# YC3122 register map
Series: ARMCM0; File version: 1.0
CPU: CM0 r1p0, little endian, no MPU, no FPU, 8 interrupt priority bits
Registers are 32-bit, read-write, reset 0x0 unless marked. A register's access mark holds for its fields unless they carry their own. Offsets are from the block's base; [hi:lo] are bit positions; <NAME> marks a mode.

## MSCI0
Base 0x000F0400
Same registers: MSCI1 0x000F0800
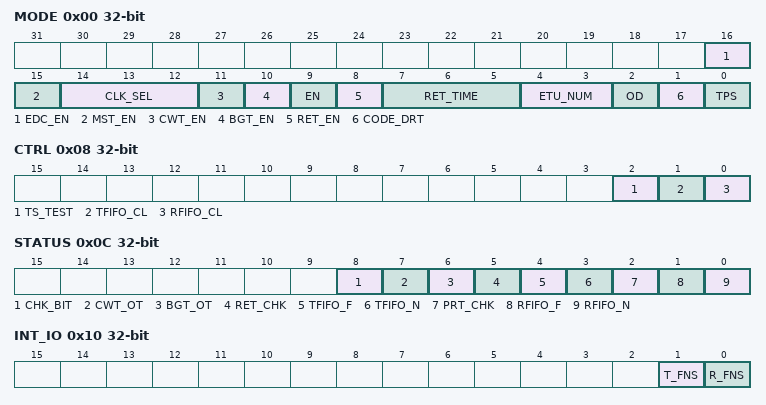
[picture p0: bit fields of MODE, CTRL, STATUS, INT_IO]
0x00 MODE
  [16] EDC_EN — EDC错误检测使能 0: 失能 1: 使能
  [15] MST_EN — 主机模式使能 0: 失能 1: 使能
  [14:12] CLK_SEL — CLK时钟源控制位(PWM0~PWM7)
  [11] CWT_EN — CWT计时器使能 0: 失能 1: 使能
  [10] BGT_EN — 块保护时间使能 0: 失能 1: 使能
  [9] EN — SCI7816使能 0: 失能 1: 使能
  [8] RET_EN — 重传使能位 0:失能 1:使能
  [7:5] RET_TIME — 重传次数
  [4:3] ETU_NUM — ETU个数控制位
  [2] OD — OD控制位 0: 开漏模式 1: 推挽模式(default)
  [1] CODE_DRT — 编码选择控制位 0:正向编码 1:反向编码
  [0] TPS — 模式控制位 0:T=0. 1:T=1
0x08 CTRL
  [2] TS_TEST — 检测TS字节 0:不起作用 1:接收到数据为03时校验位电平取反
  [1] TFIFO_CL — 发送FIFO内容清除控制位 0:不起作用 1:清除FIFO内数据
  [0] RFIFO_CL — 接收FIFO内容清除控制位 0:不起作用 1:清除FIFO内数据
0x0C STATUS
  [8] CHK_BIT — 检验位状态 0:检验位正确 1:检验位错误
  [7] CWT_OT — CWT超时状态位 0:没超时 1:超时 (参考:SCI7816_CWT寄存器说明）
  [6] BGT_OT — BGT超时状态位 0:没超时 1:超时 (参考:SCI7816_BGT寄存器说明）
  [5] RET_CHK — 重传奇偶校验检测状态位 0: 奇偶校验正确 1: 奇偶校验错误（在重传功能开启时,只有在发送达到重传 次数时仍有错误发生,此位才被置位）
  [4] TFIFO_F — 发送缓冲器满状态位 0: 发送缓冲器不满 1: 发送缓冲器满
  [3] TFIFO_N — 发送缓冲器空状态位 0: 发送缓冲器空 1: 发送缓冲器中不空
  [2] PRT_CHK — 奇偶校验状态位 0: 奇偶校验正确 1: 奇偶校验错误
  [1] RFIFO_F — 接收缓冲器满状态位 0:接收缓冲器不满 1:接收缓冲器满
  [0] RFIFO_N — 接收缓冲器空状态位 0:接收缓冲器空 1:接收缓冲器中不空
0x10 INT_IO
  [1] T_FNS — 发送完成标志位 0:没发送完成 1:已发送完成
  [0] R_FNS — 接收完成标志位 0:没接收完成 1:已接收完成
0x20 DATA
  [7:0] VAL — 在发送或接收模式下分别充当发送或接收buffer 角色
0x28 ETU
  [12:0] VAL — 配置SCI7816通讯速率
0x2C BGT
  [5:0] VAL — 配置SCI7816块反向发送时间间隔,max 6. 3
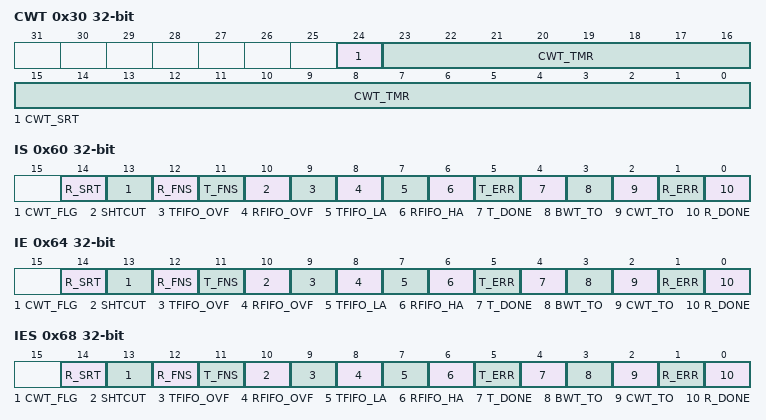
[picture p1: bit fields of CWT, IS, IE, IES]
0x30 CWT
  [24] CWT_SRT — CWT计时开始 0:CWT未开始计时 1:CWT计时立即生效
  [23:0] CWT_TMR — 配置SCI7816CWT定时值,发送字节完成,接 收起始时启动计时
0x34 EDC
  [7:0] VAL — 保存 LRC 计算结果
0x60 IS
  [14] R_SRT — 接收到毛刺信号,会触发此中断,仅rx_en使能时 会触发 bwt期间,bwt会自动恢复重启,可以触发超时 cwt期间,毛刺到来会重置cwt计数器,wt超时时间会变 长
  [13] CWT_FLG — cwt标志, 写 '1' 清除 IS 和 IES
  [12] R_FNS — 接收完成
  [11] T_FNS — 发送完成
  [10] SHTCUT
  [9] TFIFO_OVF — 主机写入 发送FIFO 时 发送FIFO 满,T. FIFO_OVF 溢出中断 接收时,主机读 FIFO 下溢可能会导致此中断断言
  [8] RFIFO_OVF — 设备接收字节时 接收FIFO 满,RFIFO_O. VF 溢出中断
  [7] TFIFO_LA — T_ITEMS <= TL_WTL 发生中断后,应首先填充T_ITEMS至水线以上,或改变水 线,才能清除中断 TL_WTL为0时,不触发此中断
  [6] RFIFO_HA — R_ITEMS <= RH_WTL 发生中断后,应首先读取rx_fifo至水线以下,或改变水 线,才能清除中断 RH_WTL为0时,不触发此中断
  [5] T_ERR — 发送错误,T0 重试次数超过配置,T1 从未触发 此错误
  [4] T_DONE — 成功传输 FIFO 中的最后一个字节
  [3] BWT_TO — 接收 BWT 定时器超时中断
  [2] CWT_TO — 接收 CWT 定时器超时中断
  [1] R_ERR — 接收错误中断,T0 重试次数超过配置,T1 奇偶 校验错误
  [0] R_DONE — 成功接收到1个字节
0x64 IE
  [14] R_SRT — 使能 R_SRT 中断控制位
  [13] CWT_FLG — 使能 CWT_FLG 中断控制位
  [12] R_FNS — 使能 R_FNS 中断控制位
  [11] T_FNS — 使能 T_FNS 中断控制位
  [10] SHTCUT — 使能 SHTCUT 中断控制位
  [9] TFIFO_OVF — 使能 TFIFO_OVF 中断控制位
  [8] RFIFO_OVF — 使能 RFIFO_OVF 中断控制位
  [7] TFIFO_LA — 使能 TFIFO_LA 中断控制位
  [6] RFIFO_HA — 使能 RFIFO_HA 中断控制位
  [5] T_ERR — 使能 T_ERR 中断控制位
  [4] T_DONE — 使能 T_DONE 中断控制位
  [3] BWT_TO — 使能 BWT_TO 中断控制位
  [2] CWT_TO — 使能 CWT_TO 中断控制位
  [1] R_ERR — 使能 R_ERR 中断控制位
  [0] R_DONE — 使能 R_DONE 中断控制位
0x68 IES
  [14] R_SRT — 使能 R_SRT 中断状态控制位
  [13] CWT_FLG — 使能 CWT_FLG 中断状态控制位
  [12] R_FNS — 使能 R_FNS 中断状态控制位
  [11] T_FNS — 使能 T_FNS 中断状态控制位
  [10] SHTCUT — 使能 SHTCUT 中断状态控制位
  [9] TFIFO_OVF — 使能 TFIFO_OVF 中断状态控制位
  [8] RFIFO_OVF — 使能 RFIFO_OVF 中断状态控制位
  [7] TFIFO_LA — 使能 TFIFO_LA 中断状态控制位
  [6] RFIFO_HA — 使能 RFIFO_HA 中断状态控制位
  [5] T_ERR — 使能 T_ERR 中断状态控制位
  [4] T_DONE — 使能 T_DONE 中断状态控制位
  [3] BWT_TO — 使能 BWT_TO 中断状态控制位
  [2] CWT_TO — 使能 CWT_TO 中断状态控制位
  [1] R_ERR — 使能 R_ERR 中断状态控制位
  [0] R_DONE — 使能 R_DONE 中断状态控制位
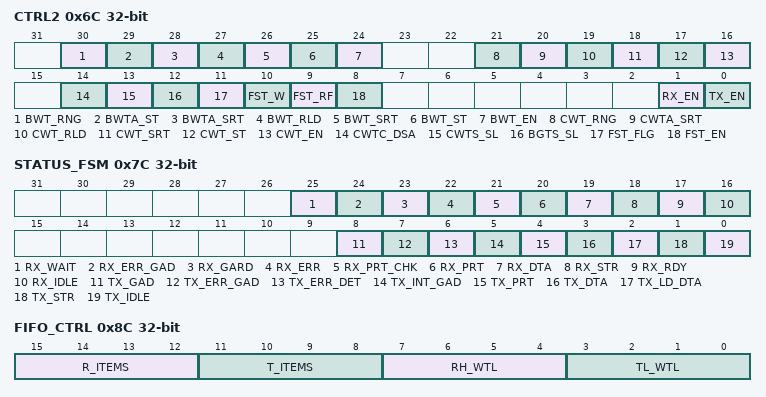
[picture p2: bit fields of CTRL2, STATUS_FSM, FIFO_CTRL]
0x6C CTRL2
  [30] BWT_RNG ro — 接收 BWT 定时器运行状态
  [29] BWTA_ST — 接收 BWT 自动停止使能控制位 0:接收 BWT 定时器不会自动停止 1:当发送”BWTA_ST”位时,接收 BWT 定时器将 自动停止
  [28] BWTA_SRT — 接收 BWT 自动启动使能控制位 0:接收 BWT 定时器不会自动启动 1:当发送”BWTA_SRT”位时,接收 BWT 定时器 将自动启动
  [27] BWT_RLD wo — 写”1”接收 BWT 重新装载,始终读回”0”
  [26] BWT_SRT wo — 写”1”接收 BWT 开始,始终读回”0”
  [25] BWT_ST wo — 写”1”接收 BWT 停止,始终读回”0”
  [24] BWT_EN — 接收 BWT 使能控制位 0:接收 BWT 定时器失能 1:接收 BWT 定时器使能
  [21] CWT_RNG ro — 接收 CWT 定时器运行状态
  [20] CWTA_SRT — 接收 CWT 自动启动使能控制位 0:接收 CWT 定时器不会自动启动 1:当发送”CWTA_SRT”位时,接收 CWT 定时器 将自动启动
  [19] CWT_RLD wo — 写”1”接收 CWT 重新装载,始终读回”0”
  [18] CWT_SRT wo — 写”1”接收 CWT 开始,始终读回”0”
  [17] CWT_ST wo — 写”1”接收 CWT 停止,始终读回”0”
  [16] CWT_EN — 接收 CWT 定时器使能控制位 0:接收 CWT 定时器失能 1:接收 CWT 定时器使能
  [14] CWTC_DSA — 清除 CWT 计数器控制位 0:使用发送开始位或接收开始位清除 CWT 计数器 1:不清除 CWT 计数器
  [13] CWTS_SL — CWT开始选择控制位 0:接收缓冲器等待或者发送字节结束 1:接收起始位或发送起始位
  [12] BGTS_SL — BGT开始选择控制位 0:接收开始 1:接收启动位,更可重新定位
  [11] FST_FLG ro — 发送第一个字节标志位 0:不传输第一个字节 1:下面的字节是要传送的第一个字节
  [10] FST_W — 发送第一个字节等待块保护时间 0:第一个字节发送不考虑 BGT_FLG. 1:当发送第一个字节时,等待 BGT_FLG 置”1”
  [9] FST_RF wo — 写1将刷新 FST_FLG 置1
  [8] FST_EN — 使能发送第一个字节控制位 0:第一个字节传输失能 1:第一个字节发送开始或当 BGT_FLG 置"1"
  [1] RX_EN — 使能接收数据控制位 0:失能 1:使能
  [0] TX_EN — 使能发送数据控制位 0:失能 1:使能
0x70 CWT_TO
  [23:0] VAL — 接收 CWT 超时预设值
0x74 CWT_RLD
  [23:0] VAL — 接收 CWT 重新加载值
0x78 CWT_CNT
  [23:0] VAL — 接收 CWT 当前计数值
0x7C STATUS_FSM
  [25] RX_WAIT ro — RX_WAIT_STATE
  [24] RX_ERR_GAD ro — RX_ERROR_GUARD_STATE
  [23] RX_GARD ro — RX_GUARD_STATE
  [22] RX_ERR ro — RX_ERROR_STATE
  [21] RX_PRT_CHK ro — RX_PARITY_CHECK_STATE
  [20] RX_PRT ro — RX_PARITY_STATE
  [19] RX_DTA ro — RX_DATA_STATE
  [18] RX_STR ro — RX_START_STATE
  [17] RX_RDY ro — RX_READY_STATE
  [16] RX_IDLE ro — RX_IDLE_STATE
  [8] TX_GAD ro — TX_GUARD_STATE
  [7] TX_ERR_GAD ro — TX_ERROR_GUARD_STATE
  [6] TX_ERR_DET ro — TX_ERROR_DETECT_STATE
  [5] TX_INT_GAD ro — TX_INT_GUARD_STATE
  [4] TX_PRT ro — TX_PARITY_STATE
  [3] TX_DTA ro — TX_DATA_STATE
  [2] TX_LD_DTA ro — TX_LOAD_DATA_STATE
  [1] TX_STR ro — TX_START_STATE
  [0] TX_IDLE ro — TX_IDLE_STATE
0x80 BWT_TO
  [23:0] VAL — 接收 BWT 超时预设值
0x84 BWT_RLD
  [23:0] VAL — 接收 BWT 重装载值
0x88 BWT_CNT
  [23:0] VAL — 接收 BWT 当前计数值
0x8C FIFO_CTRL
  [15:12] R_ITEMS ro — 接收 FIFO 字节数
  [11:8] T_ITEMS ro — 发送 FIFO 字节数
  [7:4] RH_WTL — FIFO_ITEMS >= RH_WTL 时,触 发 RFIFO_HA 中断 注意:RH_WTL 为0时,不触发中断
  [3:0] TL_WTL — T_ITEMS <= TL_WTL 时,触发 T. FIFO_LA 中断 注意：TL_WTL 为0时,不触发中断
